# cmem7 register map
File version: 1.0
Registers are 32-bit, read-write, reset 0x0 unless marked. A register's access mark holds for its fields unless they carry their own. Offsets are from the block's base; [hi:lo] are bit positions.

## ETH
Base 0x41200000
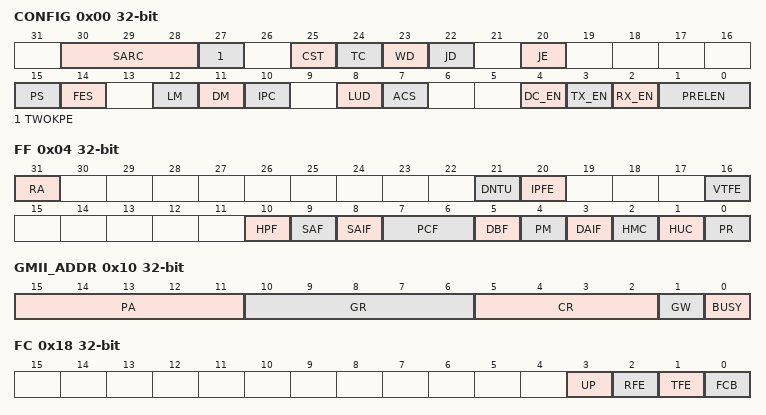
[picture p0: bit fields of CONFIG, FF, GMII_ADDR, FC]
0x00 CONFIG — MAC Configuration Register
  [30:28] SARC — Source Address Insertion or Replacement Control
  [27] TWOKPE — If 0, 1518 bytes is considered as a giant frame, 1 is 2000 bytes.
  [25] CST — CRC Stripping for Type Frames
  [24] TC — If 1, this bit enables the transmission of duplex mode, link speed, and link up or down information to the PHY
  [23] WD — Watchdog Disable
  [22] JD — if 0, the MAC cuts off the transmitter if more than 2,048 bytes of data (10,240 if JE is set high)
  [20] JE — Jumbo enable
  [15] PS — the Ethernet line speed
    0=LINE_SPEED_1000M_BPS (For 1000 Mbps operations); 1=LINE_SPEED_100M_BPS (For 10 or 100 Mbps operations)
  [14] FES — Speed in XMII interface
    0=SPEED_10M_BPS (10 Mbps); 1=SPEED_100M_BPS (100 Mbps)
  [12] LM — Loopback Mode
  [11] DM — Duplex Mode
  [10] IPC — Checksum Offload
  [8] LUD — Link Up or Down
  [7] ACS — Automatic Pad or CRC Stripping
  [4] DC_EN — Deferral Check Enable
  [3] TX_EN — Transmitter Enable
  [2] RX_EN — Receiver Enable
  [1:0] PRELEN — Preamble Length for Transmit frames
    0=PRE_LEN_7_BYTE (7 bytes of preamble); 1=PRE_LEN_5_BYTE (5 bytes of preamble); 2=PRE_LEN_3_BYTE (3 bytes of preamble)
0x04 FF — MAC Frame Filter
  [31] RA — Receive all
  [21] DNTU — Drop non-TCP/UDP over IP Frames
  [20] IPFE — Layer 3 and Layer 4 Filter Enable
  [16] VTFE — VLAN Tag Filter Enable
  [10] HPF — Hash or Perfect Filter
  [9] SAF — Source Address Filter Enable
  [8] SAIF — If set, the frames whose SA matches the SA registers are marked as failing the SA Address filter
  [7:6] PCF — Pass Control Frames
    0=PC_FILTER_ALL_CONTROL_FRAME (MAC filters all control frames); 1=PC_FORWARD_CONTROL_WITHOUT_PAUSE_FRAME (MAC forwards all control frames except Pause frames whatever Address filter); 2=PC_FORWARD_CONTROL_AND_PAUSE_FRAME (MAC forwards all control frames whatever Address filter); 3=PC_FORWARD_PASSED_CONTROL_FRAME (MAC forwards all control frames that passed Address filter)
  [5] DBF — Disable Broadcast Frames
  [4] PM — Pass All Multicast
  [3] DAIF — if set, the Address Check block operates in inverse filtering mode for the DA address comparison
  [2] HMC — if 1, don't compare DA field in destination address filtering of multicast frames with DA register
  [1] HUC — if 1, don't compare DA field in destination address filtering of unicast frames with DA register
  [0] PR — Receive all frames in spite of source and destination address
0x08 HTH — Hash Table High Register
0x0C HTL — Hash Table Low Register
0x10 GMII_ADDR — GMII Address Register
  [15:11] PA — This field indicates which of the 32 possible PHY devices are being accessed
  [10:6] GR — These bits select the desired GMII register in the selected PHY device
    0=INC_INCREMENT (Increment); 1=INC_DECREMENT (Decrement); 2=INC_NO_CHANGE (No change)
  [5:2] CR — CSR Clock Range
    0=CSR_CLOCK_60_TO_100M_MDC_DIVIDER_42 (The CSR clock frequency is 60-100 MHz and the MDC clock frequency is CSR clock/42.); 1=CSR_CLOCK_100_TO_150M_MDC_DIVIDER_62 (The CSR clock frequency is 100-150 MHz and the MDC clock frequency is CSR clock/62.); 2=CSR_CLOCK_20_TO_35M_MDC_DIVIDER_16 (The CSR clock frequency is 20-35 MHz and the MDC clock frequency is CSR clock/16.); 3=CSR_CLOCK_35_TO_60M_MDC_DIVIDER_26 (The CSR clock frequency is 35-60 MHz and the MDC clock frequency is CSR clock/26.); 4=CSR_CLOCK_150_TO_250M_MDC_DIVIDER_102 (The CSR clock frequency is 150-250 MHz and the MDC clock frequency is CSR clock/102.); 5=CSR_CLOCK_250_TO_300M_MDC_DIVIDER_124 (The CSR clock frequency is 250-300 MHz and the MDC clock frequency is CSR clock/124.); 8=CSR_CLOCK_EXTERNAL_MDC_DIVIDER_4 (The CSR clock frequency is external and the MDC clock frequency is CSR clock/4.); 9=CSR_CLOCK_EXTERNAL_MDC_DIVIDER_6 (The CSR clock frequency is external and the MDC clock frequency is CSR clock/6.); 10=CSR_CLOCK_EXTERNAL_MDC_DIVIDER_8 (The CSR clock frequency is external and the MDC clock frequency is CSR clock/8.); 11=CSR_CLOCK_EXTERNAL_MDC_DIVIDER_10 (The CSR clock frequency is external and the MDC clock frequency is CSR clock/10.); 12=CSR_CLOCK_EXTERNAL_MDC_DIVIDER_12 (The CSR clock frequency is external and the MDC clock frequency is CSR clock/12.); 13=CSR_CLOCK_EXTERNAL_MDC_DIVIDER_14 (The CSR clock frequency is external and the MDC clock frequency is CSR clock/14.); 14=CSR_CLOCK_EXTERNAL_MDC_DIVIDER_16 (The CSR clock frequency is external and the MDC clock frequency is CSR clock/16.); 15=CSR_CLOCK_EXTERNAL_MDC_DIVIDER_18 (The CSR clock frequency is external and the MDC clock frequency is CSR clock/18.)
  [1] GW — GMII write or read
  [0] BUSY — GMII Busy
0x14 GMII_DATA
0x18 FC — Flow Control Register
  [3] UP — MAC can detect Pause frames with unicast address of the station
  [2] RFE — MAC enables the flow control operation to receive Pause frames
  [1] TFE — MAC enables the flow control operation to transmit Pause frames
  [0] FCB — This bit initiates a Pause frame in the full-duplex mode
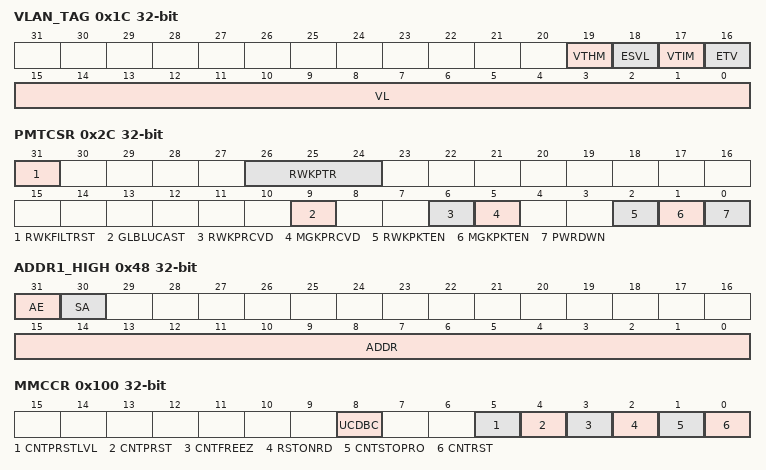
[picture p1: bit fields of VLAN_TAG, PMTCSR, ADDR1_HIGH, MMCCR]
0x1C VLAN_TAG
  [19] VTHM — When set, the most significant four bits of the VLAN tag's CRC are used to index the content
  [18] ESVL — If set, consider the S-VLAN (Type = 0x88A8) frames as valid VLAN tagged frames
  [17] VTIM — If set, The frames that do not have matching VLAN Tag are marked as matched
  [16] ETV — Enable 12-Bit VLAN Tag Comparison
  [15:0] VL — VLAN Tag Identifier for Receive Frames
0x28 RWUFFR — Remote Wake-Up Frame Filter Register
0x2C PMTCSR — PMT Control and Status Register
  [31] RWKFILTRST — Remote Wake-Up Frame Filter Register Pointer Reset.
  [26:24] RWKPTR — Remote Wake-up FIFO Pointer
  [9] GLBLUCAST — When set, enables any unicast packet filtered by the MAC (DAF)address recognition to be a remote wake-up frame.
  [6] RWKPRCVD — When set, this bit indicates the power management event is generated because of the reception of a remote wake-up frame
  [5] MGKPRCVD — the power management event is generated because of the reception of a magic packet
  [2] RWKPKTEN — Remote Wake-Up Frame Enable
  [1] MGKPKTEN — Magic Packet Enable
  [0] PWRDWN — Power Down
0x38 MACISR — Interrupt Status Register
0x3C MACIMR — Interrupt Mask Register
0x40 ADDR0_HIGH 16-bit — MAC Address0 High Register
0x44 ADDR0_LOW — MAC Address0 LOW Register
0x48 ADDR1_HIGH — MAC Address0 High Register
  [31] AE — the address filter module uses the MAC address1 for filtering
  [30] SA — MAC address1 is source or destination address compared with received frame
  [15:0] ADDR — MAC Address1 [47:32]
0x4C ADDR1_LOW — MAC Address1 LOW Register
0x100 MMCCR — MMC Control Register
  [8] UCDBC — Update MMC Counters for Dropped Broadcast Frames
  [5] CNTPRSTLVL — Counters Preset
  [4] CNTPRST — Counters Preset
  [3] CNTFREEZ — MMC Counter Freeze
  [2] RSTONRD — Reset on Read
  [1] CNTSTOPRO — Counter Stop Rollover
  [0] CNTRST — Counters Reset
0x104 MMCRIR — MMC Receive Interrupt Register
0x108 MMCTIR — MMC Transmit Interrupt Register
0x10C MMCRIMR — MMC Receive interrupt mask
0x110 MMCTIMR — MMC Transmit Interrupt Mask
0x200 MMCIRCOIM — MMC IPC Receive Checksum Offload Interrupt Mask
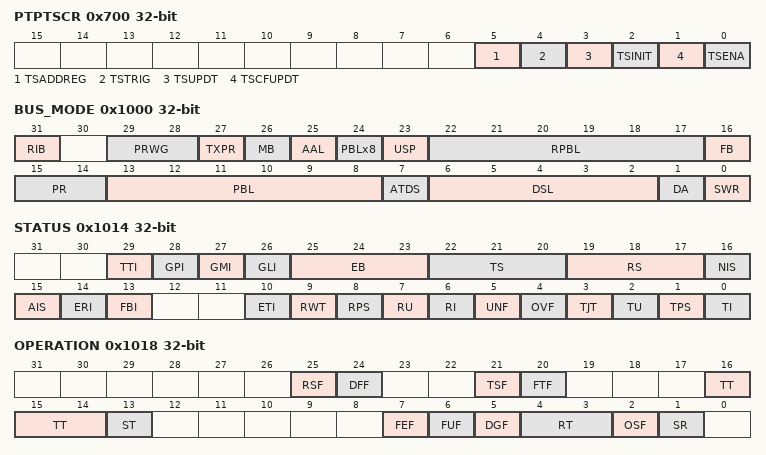
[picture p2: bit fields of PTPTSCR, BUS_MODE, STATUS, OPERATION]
0x700 PTPTSCR — Timestamp Control Register
  [5] TSADDREG — Addend Reg Update
  [4] TSTRIG — Timestamp Interrupt Trigger Enable
  [3] TSUPDT — Timestamp Update
  [2] TSINIT — Timestamp Initialize
  [1] TSCFUPDT — Timestamp Fine or Coarse Update
  [0] TSENA — Timestamp Enable
0x704 PTPSSIR — Sub-Second Increment Register
0x708 PTPTSHR — System Time – Seconds Register
0x70C PTPTSLR — System Time – Nanoseconds Register
0x710 PTPTSHUR — System Time – Seconds Update Register
0x714 PTPTSLUR — System Time – Nanoseconds Update Register
0x718 PTPTSAR — Timestamp Addend Register
0x71C PTPTTHR — Target Time Seconds Register
0x720 PTPTTLR — Target Time Nanoseconds Register
0x1000 BUS_MODE — Flow Control Register
  [31] RIB — If set, rebuilds the pending beats of any burst transfer initiated with INCRx
  [29:28] PRWG — The Priority weight is (PRWG + 1) : 1
  [27] TXPR — When set, the transmit DMA has higher priority than the receive DMA
  [26] MB — When this bit is set high and the FB bit is low, the AHB master interface starts all bursts of length more than 16 with INCR
  [25] AAL — If set, all bursts aligned to the start address LS bits
  [24] PBLx8 — If set, all PBLs multiplies 8
  [23] USP — If set, RPBL is same as RPBL definition
  [22:17] RPBL — This field indicates the maximum number of beats to be transferred in one Rx DMA transaction
  [16] FB — performs fixed burst transfers or not
  [15:14] PR — The Priority Ratio is (PR + 1) : 1
  [13:8] PBL — These bits indicate the maximum number of beats to be transferred in one DMA transaction
  [7] ATDS — When set, the size of the alternate descriptor increases to 32 bytes
  [6:2] DSL — the byte number of bus width to skip between two unchained descriptors
  [1] DA — This bit specifies the arbitration scheme between the transmit and receive paths of Channel
    0=DMA_ARBITRATION_ROUND_ROBIN (Weighted round-robin with Rx:Tx or Tx:Rx); 1=DMA_ARBITRATION_FIXED_PRIORITY (Fixed priority)
  [0] SWR — Software Reset
0x1004 TPD — Transmit Poll Demand
0x1008 RPD — Receive Poll Demand
0x100C RDESLA — Receive Descriptor List Address
0x1010 TDESLA — Transmit Descriptor List Address
0x1014 STATUS
  [29] TTI ro — Timestamp Trigger Interrupt
  [28] GPI ro — GMAC PMT Interrupt
  [27] GMI ro — GMAC MMC Interrupt
  [26] GLI ro — GMAC Line Interface Interrupt
  [25:23] EB ro — Error bit
    0=DMA_ERR_RX_WRITE_DATA_TRANSFER (Error during Rx DMA Write Data Transfer); 3=DMA_ERR_TX_READ_DATA_TRANSFER (Error during Tx DMA Read Data Transfer); 4=DMA_ERR_RX_WRITE_DESCRIPTOR (Error during Rx DMA Descriptor Write Access); 5=DMA_ERR_TX_WRITE_DESCRIPTOR (Error during Tx DMA Descriptor Write Access); 6=DMA_ERR_RX_READ_DESCRIPTOR (Error during Rx DMA Descriptor Read Access); 7=DMA_ERR_TX_READ_DESCRIPTOR (Error during Tx DMA Descriptor Read Access)
  [22:20] TS ro — Transmit DMA FSM state
    0=DMA_TRANSMIT_SM_STOP (Stopped; Reset or Stop Transmit Command issued); 1=DMA_TRANSMIT_SM_RUN_FETCH (Running: Fetching Transmit Transfer Descriptor); 2=DMA_TRANSMIT_SM_RUN_WAIT (Running: Waiting for status); 3=DMA_TRANSMIT_SM_RUN_READ (Running: Reading Data from host memory buffer and queuing it to transmit buffer (Tx FIFO)); 4=DMA_TRANSMIT_SM_TS_WRITE (TIME_STAMP write state); 6=DMA_TRANSMIT_SM_SUSPEND (Suspended; Transmit Descriptor Unavailable or Transmit Buffer Underflow); 7=DMA_TRANSMIT_SM_RUN_CLOSE (Running; Closing Transmit Descriptor)
  [19:17] RS ro — Receive DMA FSM state
    0=DMA_RECEIVE_SM_STOP (Stopped: Reset or Stop Receive Command issued); 1=DMA_RECEIVE_SM_RUN_FETCH (Running: Fetching Receive Transfer Descriptor); 3=DMA_RECEIVE_SM_RUN_WAIT (Running: Waiting for receive packet); 4=DMA_RECEIVE_SM_SUSPEND (Suspended: Receive Descriptor Unavailable); 5=DMA_RECEIVE_SM_RUN_CLOSE (Running: Closing Receive Descriptor); 6=DMA_RECEIVE_SM_TS_WRITE (TIME_STAMP write state); 7=DMA_RECEIVE_SM_RUN_TRANSFER (Running: Transferring the receive packet data from receive buffer to host memory)
  [16] NIS — Normal Interrupt Summary, must be cleared by writting
  [15] AIS — Abnormal Interrupt Summary, must be cleared by writting
  [14] ERI — the DMA filled the first data buffer of the packet
  [13] FBI — a bus error occurred, as described in EB.
  [10] ETI — the frame to be transmitted is fully transferred to the MTL Transmit FIFO
  [9] RWT — Receive Watchdog Timeout
  [8] RPS — Receive Process Stopped
  [7] RU — Receive Buffer Unavailable
  [6] RI — the frame reception is complete
  [5] UNF — Transmit Underflow
  [4] OVF — Receive Overflow
  [3] TJT — Transmit Jabber Timeout
  [2] TU — the host owns the Next Descriptor in the Transmit List and the DMA cannot acquire it.
  [1] TPS — Transmit Process Stopped
  [0] TI — This bit indicates that the frame transmission is complete
0x1018 OPERATION — Operation Mode Register
  [25] RSF — If set, the MTL reads a frame from the Rx FIFO while the complete frame has been written to it,
  [24] DFF — Disable Flushing of Received Frames
  [21] TSF — If set, transmission starts when a full frame resides in Transmit FIFO
  [20] FTF — Flush Transmit FIFO
  [16:14] TT — Transmit Threshold Control
    0=DMA_TRANSMIT_TH_64_BYTE (64 bytes); 1=DMA_TRANSMIT_TH_128_BYTE (128 bytes); 2=DMA_TRANSMIT_TH_192_BYTE (192 bytes); 3=DMA_TRANSMIT_TH_256_BYTE (256 bytes); 4=DMA_TRANSMIT_TH_40_BYTE (40 bytes); 5=DMA_TRANSMIT_TH_32_BYTE (32 bytes); 6=DMA_TRANSMIT_TH_24_BYTE (24 bytes); 7=DMA_TRANSMIT_TH_16_BYTE (16 bytes)
  [13] ST — Start or Stop Transmission Command
  [7] FEF — Forward Error Frames
  [6] FUF — Forward Undersized Good Frames
  [5] DGF — Drop Giant Frames
  [4:3] RT — Receive Threshold Control
    0=DMA_RECEIVE_TH_64_BYTE (64 bytes); 1=DMA_RECEIVE_TH_32_BYTE (32 bytes); 2=DMA_RECEIVE_TH_96_BYTE (96 bytes); 3=DMA_RECEIVE_TH_128_BYTE (128 bytes)
  [2] OSF — Operate on Second Frame
  [1] SR — Start or Stop Receive
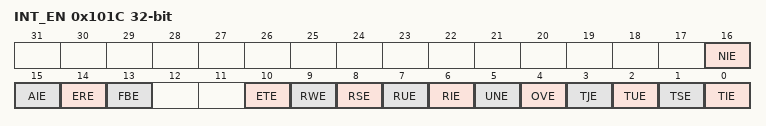
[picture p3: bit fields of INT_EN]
0x101C INT_EN — Interrupt Enable Register
  [16] NIE — Normal Interrupt Summary Enable
  [15] AIE — Abnormal Interrupt Summary Enable
  [14] ERE — Early Receive Interrupt Enable
  [13] FBE — Fatal Bus Error Enable
  [10] ETE — Early Transmit Interrupt Enable
  [9] RWE — Receive Watchdog Timeout Enable
  [8] RSE — Receive Stopped Enable
  [7] RUE — Receive Buffer Unavailable Enable
  [6] RIE — Receive Interrupt Enable
  [5] UNE — Underflow Interrupt Enable
  [4] OVE — Overflow Interrupt Enable
  [3] TJE — Transmit Jabber Timeout Enable
  [2] TUE — Transmit Buffer Unavailable Enable
  [1] TSE — Transmit Stopped Enable
  [0] TIE — Transmit Interrupt Enable
0x102C AHB_STATUS
  [0] BUSY — If set, it indicates that the AHB master interface FSMs are in the non-idle state
0x1048 CURTDESAPTR ro — Current Host Transmit Descriptor Register
0x104C CURRDESAPTR ro — Current Host Receive Descriptor Register
0x1050 CURTBUFAPTR ro — Current Host Transmit Buffer Address Register
0x1054 CURRBUFAPTR ro — Current Host Receive Buffer Address Register
